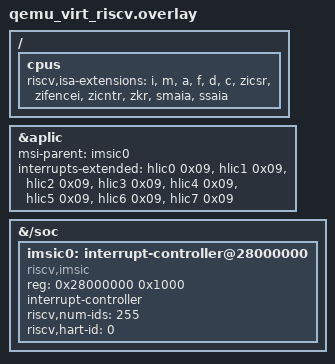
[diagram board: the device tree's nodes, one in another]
/*
 * SPDX-FileCopyrightText: Copyright The Zephyr Project Contributors
 *
 * SPDX-License-Identifier: Apache-2.0
 */

/delete-node/ &plic;

#include <qemu/virt-riscv-aia-smode.dtsi>

/ {
	cpus {
		riscv,isa-extensions = "i", "m", "a", "f", "d", "c", "zicsr", "zifencei", "zicntr",
				       "zkr", "smaia", "ssaia";
	};
};

&aplic {
	msi-parent = <&imsic0>;
	interrupts-extended = <&hlic0 0x09 &hlic1 0x09 &hlic2 0x09 &hlic3 0x09
			       &hlic4 0x09 &hlic5 0x09 &hlic6 0x09 &hlic7 0x09>;
};

&{/soc} {
	imsic0: interrupt-controller@28000000 {
		compatible = "riscv,imsic";
		reg = <0x28000000 0x1000>;
		interrupt-controller;
		#interrupt-cells = <1>;
		riscv,num-ids = <255>;
		riscv,hart-id = <0>;
		status = "okay";
	};
};
